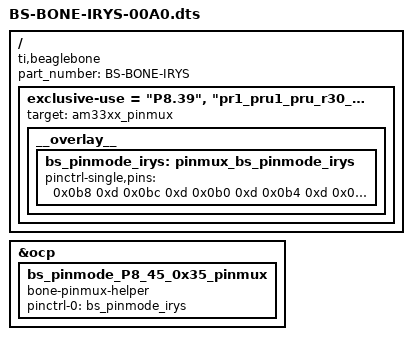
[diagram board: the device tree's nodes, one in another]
/*
 * This is a template-generated file from BoneScript
 */

/dts-v1/;
/plugin/;

/{
    compatible = "ti,beaglebone", "ti,beaglebone-black";
    part_number = "BS-BONE-IRYS";

    exclusive-use =
	"P8.39", /* Motor Left Direction*/
	"pr1_pru1_pru_r30_6",
	"P8.40", /* Motor Left Step	*/
	"pr1_pru_pru1_r30_7",
	"P8.41", /* Motor Left M0	*/
	"pr1_pru1_pru_r30_4",
	"P8.42", /* Motor Left M1	*/
	"pr1_pru1_pru_r30_5",
	"P8.43", /* Motor Right Direction*/
	"pr1_pru1_pru_r30_2",
	"P8.44", /* Motor Right Step	*/
	"pr1_pru1_pru_r30_3",
	"P8.45", /* Motor Right M0	*/
	"pr1_pru1_pru_r30_0",
	"P8.46", /* Motor Right M1	*/
	"pr1_pru1_pru_r30_1",
	"P8.12", /* Sonar Trigger 	*/
	"P8.11", /* Sonar 1 Echo	*/
	"P8.14", /* Sonar 2 Echo	*/
	"P8.15", /* Sonar 3 Echo	*/

    fragment@0 {
        target = <&am33xx_pinmux>;
        __overlay__ {
            bs_pinmode_irys: pinmux_bs_pinmode_irys {
                pinctrl-single,pins = <			
			0x0b8 0xd // P8_39 = Motor Left Direction 	= 6	
		    	0x0bc 0xd // P8_40 = Motor Left Step	 	= 7
			0x0b0 0xd // P8_41 = Motor Left M0	 	= 4
		    	0x0b4 0xd // P8_42 = Motor Left M1	 	= 5
			0x0a8 0xd // P8_43 = Motor Right Direction  	= 2
			0x0ac 0xd // P8_44 = Motor Right Step	 	= 3
			0x0a0 0xd // P8_45 = Motor Right M0  		= 0
			0x0a4 0xd // P8_46 = Motor Right M1	  	= 1
			0x030 0x7 // P8_12 = Sonar Trigger	 	
			0x034 0x27 // P8_11 = Sonar 1 Echo	  	
			0x028 0x27 // P8_14 = Sonar 2 Echo	 	
			0x03c 0x27 // P8_15 = Sonar 3 Echo	  	
		>;
            };
        };
    };

    fragment@1 {
        target = <&ocp>;
        __overlay__ {
            bs_pinmode_P8_45_0x35_pinmux {
                compatible = "bone-pinmux-helper";
                status = "okay";
                pinctrl-names = "default";
                pinctrl-0 = <&bs_pinmode_irys>;
            };
        };
    };
};

